AUTOSAR XML (schema 4-3-0)
package /Dimmer
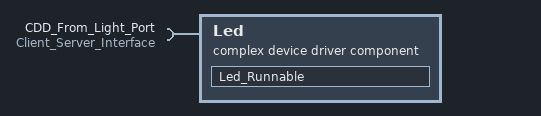
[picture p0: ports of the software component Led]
  complex device driver sw component type Led
    require port CDD_From_Light_Port: client-com-spec=Op1, required-interface=Client_Server_Interface
    behavior Led_InternalBehavior
      events:
        init event Led_Event: start-on-event=Led_Runnable
      runnable Led_Runnable
  swc implementation Led_Implementation: behavior=Led_InternalBehavior
